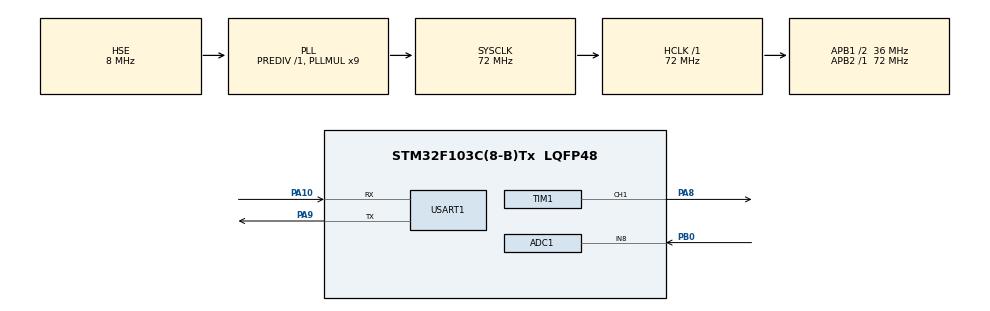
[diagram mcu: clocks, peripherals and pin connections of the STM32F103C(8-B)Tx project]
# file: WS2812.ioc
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ADC1.Channel-0\#ChannelRegularConversion=ADC_CHANNEL_8
ADC1.NbrOfConversionFlag=1
ADC1.Rank-0\#ChannelRegularConversion=1
ADC1.SamplingTime-0\#ChannelRegularConversion=ADC_SAMPLETIME_1CYCLE_5
ADC1.master=1
Dma.Request0=TIM1_CH1
Dma.TIM1_CH1.0.Direction=DMA_MEMORY_TO_PERIPH
Dma.TIM1_CH1.0.Instance=DMA1_Channel2
Dma.TIM1_CH1.0.MemDataAlignment=DMA_MDATAALIGN_WORD
Dma.TIM1_CH1.0.MemInc=DMA_MINC_ENABLE
Dma.TIM1_CH1.0.Mode=DMA_NORMAL
Dma.TIM1_CH1.0.PeriphDataAlignment=DMA_PDATAALIGN_WORD
Dma.TIM1_CH1.0.PeriphInc=DMA_PINC_DISABLE
Dma.TIM1_CH1.0.Priority=DMA_PRIORITY_LOW
Mcu.Family=STM32F1
Mcu.Name=STM32F103C(8-B)Tx
Mcu.Package=LQFP48
NVIC.DMA1_Channel2_IRQn=true\:0\:0\:false\:false\:true\:false\:true
NVIC.PriorityGroup=NVIC_PRIORITYGROUP_4
NVIC.TIM2_IRQn=true\:0\:0\:false\:false\:true\:true\:true
NVIC.USART1_IRQn=true\:0\:0\:false\:false\:true\:true\:true
PA10.Mode=Asynchronous
PA10.Signal=USART1_RX
PA13.Mode=Serial_Wire
PA13.Signal=SYS_JTMS-SWDIO
PA14.Mode=Serial_Wire
PA14.Signal=SYS_JTCK-SWCLK
PA8.Signal=S_TIM1_CH1
PA9.Mode=Asynchronous
PA9.Signal=USART1_TX
PB0.Signal=ADCx_IN8
PD0-OSC_IN.Mode=HSE-External-Oscillator
PD0-OSC_IN.Signal=RCC_OSC_IN
PD1-OSC_OUT.Mode=HSE-External-Oscillator
PD1-OSC_OUT.Signal=RCC_OSC_OUT
ProjectManager.HeapSize=0x200
ProjectManager.StackSize=0x400
ProjectManager.TargetToolchain=MDK-ARM V5.27
RCC.ADCPresc=RCC_ADCPCLK2_DIV6
RCC.AHBFreq_Value=72000000
RCC.APB1CLKDivider=RCC_HCLK_DIV2
RCC.APB1Freq_Value=36000000
RCC.APB1TimFreq_Value=72000000
RCC.APB2Freq_Value=72000000
RCC.APB2TimFreq_Value=72000000
RCC.HCLKFreq_Value=72000000
RCC.PLLMUL=RCC_PLL_MUL9
RCC.PLLSourceVirtual=RCC_PLLSOURCE_HSE
RCC.SYSCLKFreq_VALUE=72000000
RCC.SYSCLKSource=RCC_SYSCLKSOURCE_PLLCLK
RCC.USBFreq_Value=72000000
SH.ADCx_IN8.0=ADC1_IN8,IN8
SH.S_TIM1_CH1.0=TIM1_CH1,PWM Generation1 CH1
TIM1.Channel-PWM\ Generation1\ CH1=TIM_CHANNEL_1
TIM1.Period=90-1
TIM2.Period=100-1
TIM2.Prescaler=720
USART1.VirtualMode=VM_ASYNC
VP_TIM1_VS_ClockSourceINT.Mode=Internal
VP_TIM2_VS_ClockSourceINT.Mode=Internal
board=custom

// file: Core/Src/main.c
/* USER CODE BEGIN Header */
/**
  ******************************************************************************
  * @file           : main.c
  * @brief          : Main program body
  ******************************************************************************
  * @attention
  *
  * <h2><center>&copy; Copyright (c) 2023 STMicroelectronics.
  * All rights reserved.</center></h2>
  *
  * This software component is licensed by ST under BSD 3-Clause license,
  * the "License"; You may not use this file except in compliance with the
  * License. You may obtain a copy of the License at:
  *                        opensource.org/licenses/BSD-3-Clause
  *
  ******************************************************************************
  */
/* USER CODE END Header */
#include "main.h"
#include "adc.h"
#include "dma.h"
#include "tim.h"
#include "usart.h"
#include "gpio.h"

/* USER CODE BEGIN Includes */
#include "WS2812.h"

/* USER CODE END Includes */

/* USER CODE BEGIN PV */
//uint32_t adc_value = 0;
uint32_t g_current_led_cnt = 10;      //初始化点灯数量
ledMode_typ g_mode;    //指定LED模式
uint8_t RX_buff[2];   //Uart1的接收缓冲区，uint8_t类型也是串口接收中断函数指定的；实际只需要用户发送一个字符就行,这个设置2个字节是为了防止溢出而已
/* USER CODE END PV */

void SystemClock_Config(void);

/* USER CODE BEGIN 0 */
void HAL_TIM_PWM_PulseFinishedCallback(TIM_HandleTypeDef *htim)
{
  WS2812_Send();
}

/* USER CODE END 0 */

int main(void)
{

  /* MCU Configuration--------------------------------------------------------*/

  /* Reset of all peripherals, Initializes the Flash interface and the Systick. */
  HAL_Init();

  /* Configure the system clock */
  SystemClock_Config();

  /* Initialize all configured peripherals */
  MX_GPIO_Init();
  MX_DMA_Init();
  MX_TIM1_Init();
  MX_ADC1_Init();
  MX_USART1_UART_Init();
  MX_TIM2_Init();
  /* USER CODE BEGIN 2 */
	HAL_TIM_Base_Start_IT(&htim2);
	HAL_UART_Receive_IT(&huart1,RX_buff,1);   //开启Uart1的接收中断，然后到相应的中断服务函数(Callback)中去处理即可,用户只发一个字母即可

  //for (int i = 0; i < WS2812_Num; i++)    //给每个LED设置颜色值
    //WS2812_Data[i] = 0x0000FF;
	printf("WS2812 runing...");

  /* USER CODE END 2 */

  /* Infinite loop */
  while (1)
  {

    /* USER CODE BEGIN 3 */

		//led_mode_breath();     //呼吸灯

		//led_mode_marquee();   //流水灯
	  //led_mode_music();
		led_mode_select();       //扫描www.hc01.com主页的微信小程序,选择HC-04BLE后默认是呼吸灯,输入A流水灯,M音乐灯,再输入B则呼吸灯
		//HAL_Delay(50);
  }
  /* USER CODE END 3 */
}

void SystemClock_Config(void)
{
  RCC_OscInitTypeDef RCC_OscInitStruct = {0};
  RCC_ClkInitTypeDef RCC_ClkInitStruct = {0};
  RCC_PeriphCLKInitTypeDef PeriphClkInit = {0};

  /** Initializes the RCC Oscillators according to the specified parameters
  * in the RCC_OscInitTypeDef structure.
  */
  RCC_OscInitStruct.OscillatorType = RCC_OSCILLATORTYPE_HSE;
  RCC_OscInitStruct.HSEState = RCC_HSE_ON;
  RCC_OscInitStruct.HSEPredivValue = RCC_HSE_PREDIV_DIV1;
  RCC_OscInitStruct.HSIState = RCC_HSI_ON;
  RCC_OscInitStruct.PLL.PLLState = RCC_PLL_ON;
  RCC_OscInitStruct.PLL.PLLSource = RCC_PLLSOURCE_HSE;
  RCC_OscInitStruct.PLL.PLLMUL = RCC_PLL_MUL9;
  if (HAL_RCC_OscConfig(&RCC_OscInitStruct) != HAL_OK)
  {
    Error_Handler();
  }
  /** Initializes the CPU, AHB and APB buses clocks
  */
  RCC_ClkInitStruct.ClockType = RCC_CLOCKTYPE_HCLK|RCC_CLOCKTYPE_SYSCLK
                              |RCC_CLOCKTYPE_PCLK1|RCC_CLOCKTYPE_PCLK2;
  RCC_ClkInitStruct.SYSCLKSource = RCC_SYSCLKSOURCE_PLLCLK;
  RCC_ClkInitStruct.AHBCLKDivider = RCC_SYSCLK_DIV1;
  RCC_ClkInitStruct.APB1CLKDivider = RCC_HCLK_DIV2;
  RCC_ClkInitStruct.APB2CLKDivider = RCC_HCLK_DIV1;

  if (HAL_RCC_ClockConfig(&RCC_ClkInitStruct, FLASH_LATENCY_2) != HAL_OK)
  {
    Error_Handler();
  }
  PeriphClkInit.PeriphClockSelection = RCC_PERIPHCLK_ADC;
  PeriphClkInit.AdcClockSelection = RCC_ADCPCLK2_DIV6;
  if (HAL_RCCEx_PeriphCLKConfig(&PeriphClkInit) != HAL_OK)
  {
    Error_Handler();
  }
}

void Error_Handler(void)
{
  __disable_irq();
  while (1)
  {
  }
}

/************************ (C) COPYRIGHT STMicroelectronics *****END OF FILE****/
